VERSION ""

NS_ :

BS_:

BU_: XXX

BO_ 85 CID_ERABSH: 8 XXX
 SG_ sig_twactk : 40|1@1+ (1,0) [0|1] "" XXX
 SG_ sig_pllnsu : 56|8@1+ (1,0) [0|255] "" XXX

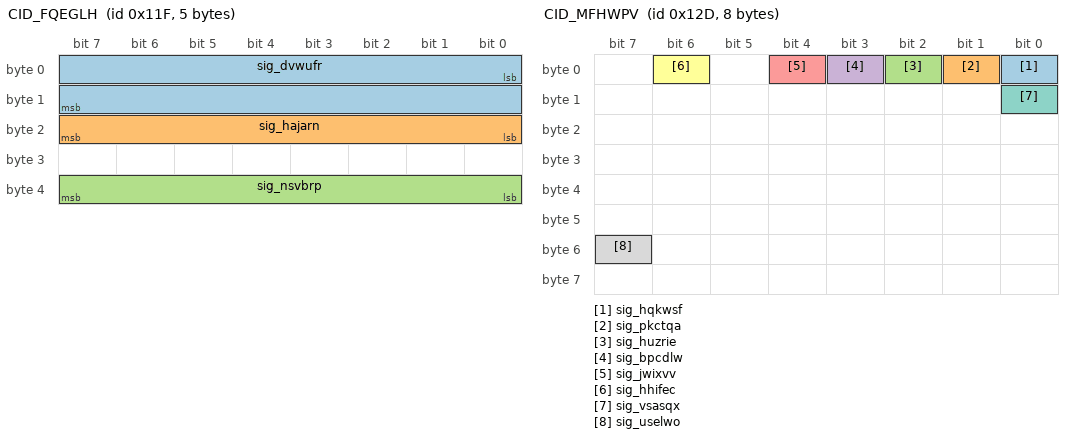
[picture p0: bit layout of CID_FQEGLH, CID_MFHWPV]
BO_ 287 CID_FQEGLH: 5 XXX
 SG_ sig_dvwufr : 0|16@1- (0.1,0) [-450|450] "" XXX
 SG_ sig_hajarn : 16|8@1+ (4,0) [0|1020] "" XXX
 SG_ sig_nsvbrp : 32|8@1+ (1,0) [0|255] "" XXX

BO_ 289 CID_NCPCTA: 8 XXX
 SG_ sig_chrfgo : 0|12@1+ (1,0) [0|255] "" XXX

BO_ 301 CID_MFHWPV: 8 XXX
 SG_ sig_hqkwsf : 0|1@0+ (1,0) [0|1] "" XXX
 SG_ sig_pkctqa : 1|1@0+ (1,0) [0|1] "" XXX
 SG_ sig_huzrie : 2|1@0+ (1,0) [0|1] "" XXX
 SG_ sig_bpcdlw : 3|1@0+ (1,0) [0|1] "" XXX
 SG_ sig_jwixvv : 4|1@0+ (1,0) [0|1] "" XXX
 SG_ sig_hhifec : 6|1@0+ (1,0) [0|1] "" XXX
 SG_ sig_vsasqx : 8|1@0+ (1,0) [0|1] "" XXX
 SG_ sig_uselwo : 55|1@0+ (1,0) [0|1] "" XXX

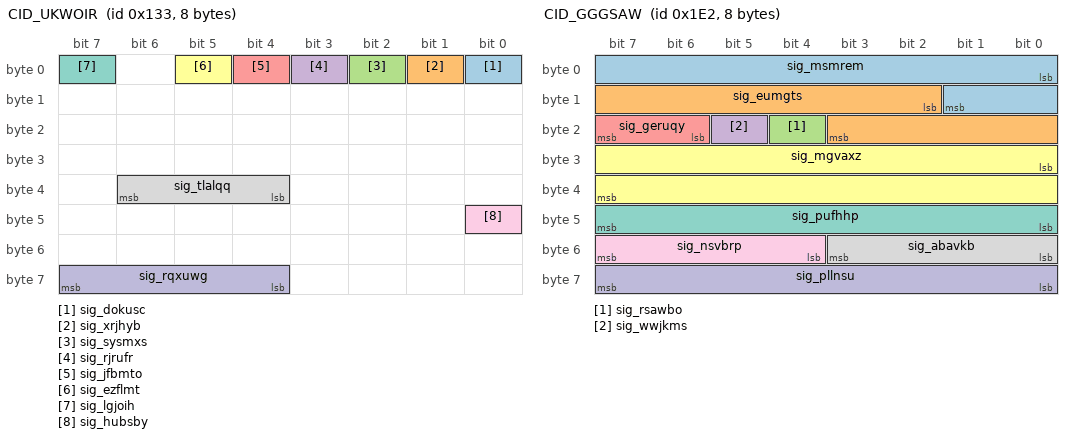
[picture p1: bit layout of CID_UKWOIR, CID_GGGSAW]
BO_ 307 CID_UKWOIR: 8 XXX
 SG_ sig_dokusc : 0|1@0+ (1,0) [0|1] "" XXX
 SG_ sig_xrjhyb : 1|1@1+ (1,0) [0|1] "" XXX
 SG_ sig_sysmxs : 2|1@1+ (1,0) [0|1] "" XXX
 SG_ sig_rjrufr : 3|1@1+ (1,0) [0|1] "" XXX
 SG_ sig_jfbmto : 4|1@0+ (1,0) [0|1] "" XXX
 SG_ sig_ezflmt : 5|1@0+ (1,0) [0|1] "" XXX
 SG_ sig_lgjoih : 7|1@0+ (1,0) [0|1] "" XXX
 SG_ sig_tlalqq : 36|3@1+ (1,0) [0|7] "" XXX
 SG_ sig_hubsby : 40|1@0+ (1,0) [0|1] "" XXX
 SG_ sig_rqxuwg : 63|4@0+ (1,0) [0|15] "" XXX

BO_ 482 CID_GGGSAW: 8 XXX
 SG_ sig_msmrem : 0|10@1- (0.01,0) [0|5] "" XXX
 SG_ sig_eumgts : 10|10@1- (0.01,0) [-5|0] "" XXX
 SG_ sig_rsawbo : 20|1@0+ (1,0) [0|1] "" XXX
 SG_ sig_wwjkms : 21|1@0+ (1,0) [0|1] "" XXX
 SG_ sig_geruqy : 22|2@1+ (1,0) [0|1] "" XXX
 SG_ sig_mgvaxz : 24|16@1- (0.1,0) [-780|779.9] "" XXX
 SG_ sig_pufhhp : 47|8@0+ (1,0) [0|255] "" XXX
 SG_ sig_abavkb : 48|4@1+ (1,0) [0|15] "" XXX
 SG_ sig_nsvbrp : 52|4@1+ (1,0) [0|15] "" XXX
 SG_ sig_pllnsu : 56|8@1+ (1,0) [0|255] "" XXX

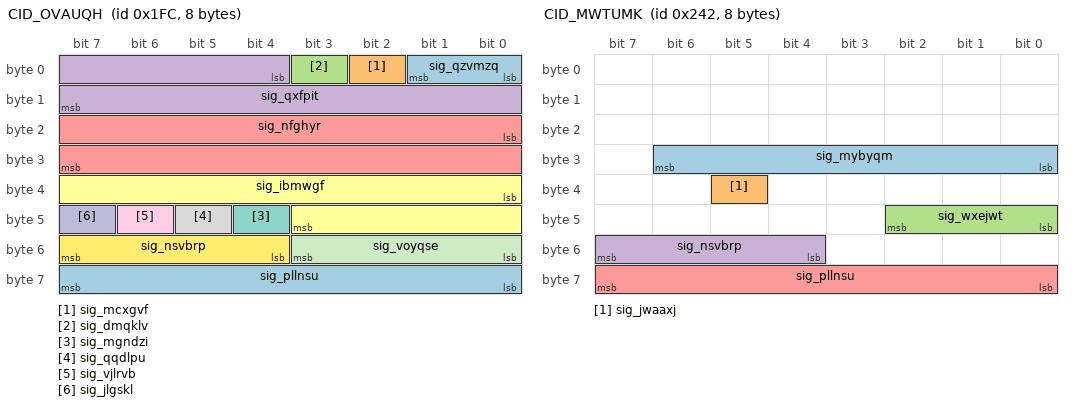
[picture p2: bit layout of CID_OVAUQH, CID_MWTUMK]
BO_ 508 CID_OVAUQH: 8 XXX
 SG_ sig_qzvmzq : 0|2@1+ (1,0) [0|1] "" XXX
 SG_ sig_mcxgvf : 2|1@1+ (1,0) [0|1] "" XXX
 SG_ sig_dmqklv : 3|1@0+ (1,0) [0|1] "" XXX
 SG_ sig_qxfpit : 4|12@1- (1,0) [-2048|2047] "" XXX
 SG_ sig_nfghyr : 16|16@1- (0.1,0) [-780|779.9] "Deg" XXX
 SG_ sig_ibmwgf : 32|12@1- (0.01,0) [0|63] "" XXX
 SG_ sig_mgndzi : 44|1@0+ (1,0) [0|1] "" XXX
 SG_ sig_qqdlpu : 45|1@1+ (1,0) [0|255] "" XXX
 SG_ sig_vjlrvb : 46|1@1+ (1,0) [0|1] "" XXX
 SG_ sig_jlgskl : 47|1@0+ (1,0) [0|3] "" XXX
 SG_ sig_voyqse : 48|4@1+ (1,0) [0|15] "" XXX
 SG_ sig_nsvbrp : 52|4@1+ (1,0) [0|15] "" XXX
 SG_ sig_pllnsu : 56|8@1+ (1,0) [0|255] "" XXX

BO_ 578 CID_MWTUMK: 8 XXX
 SG_ sig_mybyqm : 30|7@0+ (1,0) [0|127] "" XXX
 SG_ sig_jwaaxj : 37|1@0+ (1,0) [0|1] "" XXX
 SG_ sig_wxejwt : 40|3@1+ (1,0) [0|7] "" XXX
 SG_ sig_nsvbrp : 55|4@0+ (1,0) [0|15] "" XXX
 SG_ sig_pllnsu : 56|8@1+ (1,0) [0|255] "" XXX

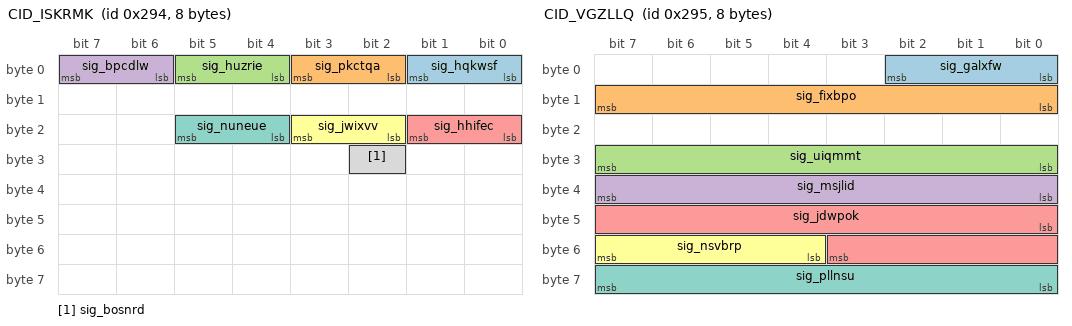
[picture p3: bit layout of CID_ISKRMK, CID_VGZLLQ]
BO_ 660 CID_ISKRMK: 8 XXX
 SG_ sig_hqkwsf : 1|2@0+ (1,0) [0|3] "" XXX
 SG_ sig_pkctqa : 3|2@0+ (1,0) [0|3] "" XXX
 SG_ sig_huzrie : 5|2@0+ (1,0) [0|3] "" XXX
 SG_ sig_bpcdlw : 7|2@0+ (1,0) [0|3] "" XXX
 SG_ sig_hhifec : 17|2@0+ (1,0) [0|3] "" XXX
 SG_ sig_jwixvv : 19|2@0+ (1,0) [0|3] "" XXX
 SG_ sig_nuneue : 21|2@0+ (1,0) [0|3] "" XXX
 SG_ sig_bosnrd : 26|1@0+ (1,0) [0|1] "" XXX

BO_ 661 CID_VGZLLQ: 8 XXX
 SG_ sig_galxfw : 2|3@0+ (1,0) [0|7] "" XXX
 SG_ sig_fixbpo : 15|8@0+ (1,0) [0|255] "" XXX
 SG_ sig_uiqmmt : 31|8@0+ (1,0) [0|255] "" XXX
 SG_ sig_msjlid : 32|8@1+ (1,0) [0|255] "" XXX
 SG_ sig_jdwpok : 40|12@1+ (1,0) [0|255] "" XXX
 SG_ sig_nsvbrp : 52|4@1+ (1,0) [0|15] "" XXX
 SG_ sig_pllnsu : 63|8@0+ (1,0) [0|255] "" XXX

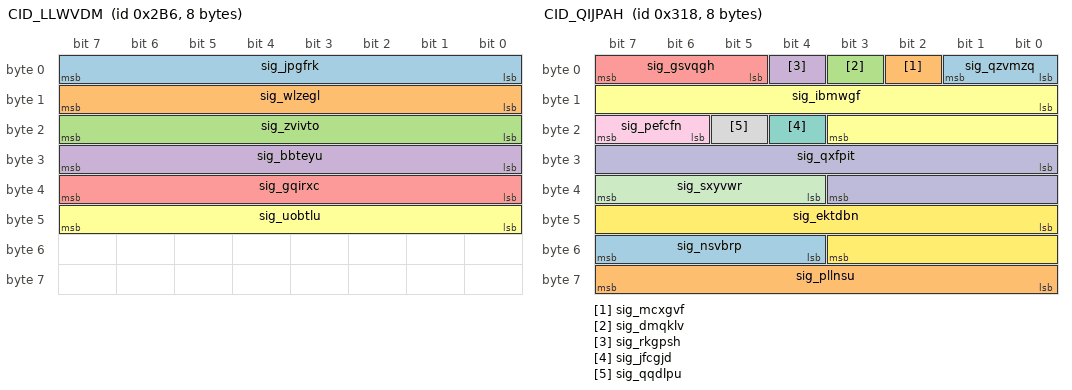
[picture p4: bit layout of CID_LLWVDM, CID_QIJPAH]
BO_ 694 CID_LLWVDM: 8 XXX
 SG_ sig_jpgfrk : 7|8@0+ (1,0) [0|255] "" XXX
 SG_ sig_wlzegl : 15|8@0+ (1,0) [0|255] "" XXX
 SG_ sig_zvivto : 23|8@0+ (1,0) [0|255] "" XXX
 SG_ sig_bbteyu : 31|8@0+ (1,0) [0|255] "" XXX
 SG_ sig_gqirxc : 39|8@0+ (1,0) [0|255] "" XXX
 SG_ sig_uobtlu : 47|8@0+ (1,0) [0|255] "" XXX

BO_ 790 CID_IHYLFP: 8 XXX
 SG_ sig_yiwmwi : 3|4@0+ (1,0) [0|1] "" XXX
 SG_ sig_asaiym : 4|2@1+ (1,0) [0|3] "" XXX
 SG_ sig_ujzcro : 6|2@1+ (1,0) [0|3] "" XXX
 SG_ sig_ppxvnu : 8|2@1+ (1,0) [0|3] "" XXX
 SG_ sig_ufomys : 10|1@1+ (1,0) [0|1] "" XXX
 SG_ sig_vddbsz : 11|4@1+ (1,0) [0|1] "" XXX
 SG_ sig_ttslhu : 15|1@0+ (1,0) [0|1] "" XXX
 SG_ sig_mgvaxz : 16|11@1- (1,0) [-1024|1023] "" XXX
 SG_ sig_rsawbo : 27|1@1+ (1,0) [0|1] "" XXX
 SG_ sig_wwjkms : 28|1@1+ (1,0) [0|3] "" XXX
 SG_ sig_pwhlfk : 29|1@0+ (1,0) [0|1] "" XXX
 SG_ sig_rqfpio : 30|1@0+ (1,0) [0|1] "" XXX
 SG_ sig_guihfw : 31|1@0+ (1,0) [0|1] "" XXX
 SG_ sig_iqlfnf : 32|2@1+ (1,0) [0|3] "" XXX
 SG_ sig_sonppl : 34|2@1+ (1,0) [0|3] "" XXX
 SG_ sig_ppvyhq : 36|4@1+ (1,0) [0|3] "" XXX
 SG_ sig_fupsdz : 40|8@1+ (5,-5) [-5|1270] "" XXX
 SG_ sig_xygpyq : 49|2@0+ (1,0) [0|3] "" XXX
 SG_ sig_pidyni : 51|2@0+ (1,0) [0|3] "" XXX
 SG_ sig_nsvbrp : 52|4@1+ (1,0) [0|15] "" XXX
 SG_ sig_pllnsu : 56|8@1+ (1,0) [0|15] "" XXX

BO_ 792 CID_QIJPAH: 8 XXX
 SG_ sig_qzvmzq : 0|2@1+ (1,0) [0|1] "" XXX
 SG_ sig_mcxgvf : 2|1@1+ (1,0) [0|1] "" XXX
 SG_ sig_dmqklv : 3|1@1+ (1,0) [0|1] "" XXX
 SG_ sig_rkgpsh : 4|1@1+ (1,0) [0|1] "" XXX
 SG_ sig_gsvqgh : 5|3@1+ (1,0) [0|1] "" XXX
 SG_ sig_ibmwgf : 8|12@1- (1,0) [-2048|2047] "" XXX
 SG_ sig_jfcgjd : 20|1@1+ (1,0) [0|1] "" XXX
 SG_ sig_qqdlpu : 21|1@1+ (1,0) [0|1] "" XXX
 SG_ sig_pefcfn : 22|2@1+ (1,0) [0|15] "" XXX
 SG_ sig_qxfpit : 24|12@1- (1,0) [-2048|2047] "" XXX
 SG_ sig_sxyvwr : 36|4@1+ (1,0) [0|15] "" XXX
 SG_ sig_ektdbn : 40|12@1+ (1,0) [0|4095] "" XXX
 SG_ sig_nsvbrp : 52|4@1+ (1,0) [0|15] "" XXX
 SG_ sig_pllnsu : 56|8@1+ (1,0) [0|255] "" XXX

BO_ 813 CID_ZQVDSF: 8 XXX
 SG_ sig_lllhgp : 0|9@1+ (0.5,0) [0|255.5] "" XXX
 SG_ sig_jggloe : 9|1@1+ (1,0) [0|1] "" XXX
 SG_ sig_tagrcv : 10|3@1+ (1,0) [0|7] "" XXX
 SG_ sig_yhjoqu : 13|3@1+ (1,0) [0|7] "" XXX
 SG_ sig_gesmbk : 16|1@1+ (1,0) [0|1] "" XXX
 SG_ sig_vnttzo : 17|1@1+ (1,0) [0|1] "" XXX
 SG_ sig_dmqklv : 18|1@1+ (1,0) [0|1] "" XXX
 SG_ sig_zqnlqf : 19|3@1+ (1,0) [0|1] "" XXX
 SG_ sig_korvsq : 22|1@0+ (1,0) [0|1] "" XXX
 SG_ sig_lfufbj : 23|1@0+ (1,0) [0|1] "" XXX
 SG_ sig_ppxvnu : 24|1@1+ (1,0) [0|1] "" XXX
 SG_ sig_vjhzxb : 25|7@1+ (1,0) [0|127] "" XXX
 SG_ sig_ljyeyu : 32|4@1+ (1,0) [0|15] "" XXX
 SG_ sig_upchqc : 36|12@1+ (1,0) [0|4095] "" XXX
 SG_ sig_nsvbrp : 48|4@1+ (1,0) [0|15] "" XXX
 SG_ sig_appgiu : 55|4@0+ (1,0) [0|15] "" XXX
 SG_ sig_pllnsu : 56|8@1+ (1,0) [0|255] "" XXX

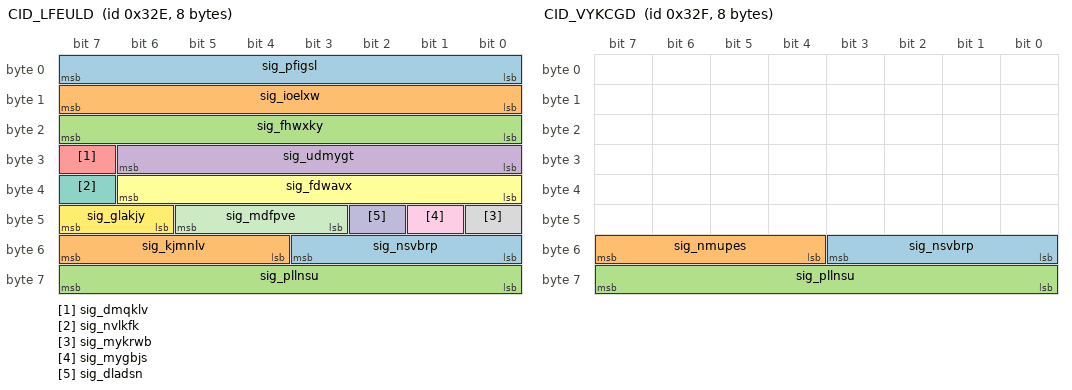
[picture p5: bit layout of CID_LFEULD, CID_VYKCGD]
BO_ 814 CID_LFEULD: 8 XXX
 SG_ sig_pfigsl : 0|8@1+ (0.05,-5) [-100|155] "" XXX
 SG_ sig_ioelxw : 8|8@1+ (0.05,-5) [0|1.26] "" XXX
 SG_ sig_fhwxky : 16|8@1+ (0.05,-5) [0|1.26] "" XXX
 SG_ sig_udmygt : 24|7@1+ (0.2,0) [0|12.7] "" XXX
 SG_ sig_dmqklv : 31|1@0+ (1,0) [0|1] "" XXX
 SG_ sig_fdwavx : 32|7@1+ (0.2,-16) [0|12.7] "" XXX
 SG_ sig_nvlkfk : 39|1@0+ (1,0) [0|1] "" XXX
 SG_ sig_mykrwb : 40|1@0+ (1,0) [0|1] "" XXX
 SG_ sig_mygbjs : 41|1@0+ (1,0) [0|1] "" XXX
 SG_ sig_dladsn : 42|1@1+ (1,0) [0|3] "" XXX
 SG_ sig_mdfpve : 45|3@0+ (1,0) [0|1] "" XXX
 SG_ sig_glakjy : 46|2@1+ (1,0) [0|3] "" XXX
 SG_ sig_nsvbrp : 48|4@1+ (1,0) [0|15] "" XXX
 SG_ sig_kjmnlv : 55|4@0+ (1,0) [0|15] "" XXX
 SG_ sig_pllnsu : 56|8@1+ (1,0) [0|255] "" XXX

BO_ 815 CID_VYKCGD: 8 XXX
 SG_ sig_nsvbrp : 48|4@1+ (1,0) [0|15] "" XXX
 SG_ sig_nmupes : 55|4@0+ (1,0) [0|15] "" XXX
 SG_ sig_pllnsu : 56|8@1+ (1,0) [0|255] "" XXX

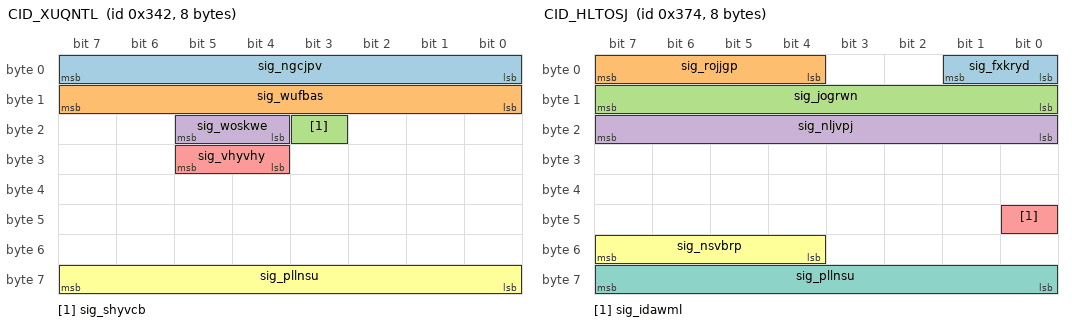
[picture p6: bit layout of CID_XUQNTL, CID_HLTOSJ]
BO_ 834 CID_XUQNTL: 8 XXX
 SG_ sig_ngcjpv : 0|8@1+ (0.01,0) [0|2.55] "" XXX
 SG_ sig_wufbas : 8|8@1+ (0.01,0) [0|2.55] "" XXX
 SG_ sig_shyvcb : 19|1@1+ (1,0) [0|1] "" XXX
 SG_ sig_woskwe : 20|2@1+ (1,0) [0|255] "" XXX
 SG_ sig_vhyvhy : 28|2@1+ (1,0) [0|1] "" XXX
 SG_ sig_pllnsu : 56|8@1+ (1,0) [0|255] "" XXX

BO_ 884 CID_HLTOSJ: 8 XXX
 SG_ sig_fxkryd : 1|2@0+ (1,0) [0|3] "" XXX
 SG_ sig_rojjgp : 7|4@0+ (1,0) [0|15] "" XXX
 SG_ sig_jogrwn : 15|8@0+ (0.1,-12) [0|255] "" XXX
 SG_ sig_nljvpj : 23|8@0+ (1,-100) [0|255] "" XXX
 SG_ sig_idawml : 40|1@0+ (1,0) [0|3] "" XXX
 SG_ sig_nsvbrp : 52|4@1+ (1,0) [0|15] "" XXX
 SG_ sig_pllnsu : 56|8@1+ (1,0) [0|255] "" XXX

BO_ 944 CID_HXWUYZ: 8 XXX
 SG_ sig_optigr : 1|2@0+ (1,0) [0|3] "" XXX
 SG_ sig_ljqrtd : 2|1@0+ (1,0) [0|1] "" XXX
 SG_ sig_urkcxn : 4|2@0+ (1,0) [0|3] "" XXX
 SG_ sig_yyklty : 5|1@0+ (1,0) [0|1] "" XXX
 SG_ sig_dauvqh : 6|1@0+ (1,0) [0|1] "" XXX
 SG_ sig_hklgix : 7|1@0+ (1,0) [0|1] "" XXX
 SG_ sig_fxhrlt : 8|1@0+ (1,0) [0|1] "" XXX
 SG_ sig_dsxdaz : 11|3@0+ (1,0) [0|7] "" XXX
 SG_ sig_kgquts : 12|1@0+ (1,0) [0|1] "" XXX
 SG_ sig_fgorot : 14|2@0+ (1,0) [0|3] "" XXX
 SG_ sig_gzwdpi : 15|1@0+ (1,0) [0|1] "" XXX
 SG_ sig_ygfaoj : 16|1@0+ (1,0) [0|1] "" XXX
 SG_ sig_butnkb : 18|2@0+ (1,0) [0|3] "" XXX
 SG_ sig_xyvooe : 19|1@0+ (1,0) [0|1] "" XXX
 SG_ sig_icifsz : 23|4@0+ (1,0) [0|15] "" XXX
 SG_ sig_svozqt : 24|28@1+ (1,0) [0|268435455] "" XXX
 SG_ sig_nsvbrp : 52|4@1+ (1,0) [0|15] "" XXX
 SG_ sig_pllnsu : 56|8@1+ (1,0) [0|255] "" XXX

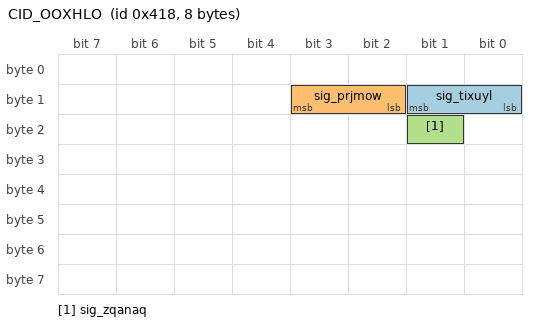
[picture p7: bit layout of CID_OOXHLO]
BO_ 1048 CID_OOXHLO: 8 XXX
 SG_ sig_tixuyl : 9|2@0+ (1,0) [0|1] "" XXX
 SG_ sig_prjmow : 11|2@0+ (1,0) [0|1] "" XXX
 SG_ sig_zqanaq : 17|1@0+ (1,0) [0|1] "" XXX

VAL_ 578 sig_wxejwt 4 "D" 2 "R" 3 "N" 1 "P";
VAL_ 790 sig_yiwmwi 11 "AutoFullBeamActive" 2 "AutoFullBeamInactive";
VAL_ 790 sig_asaiym 0 "GRAY" 1 "GREEN" 2 "YELLOW" 3 "RED";
VAL_ 790 sig_ujzcro 3 "ALARM_AND_LKA" 2 "LKA" 1 "ALARM" 0 "DISABLE";
VAL_ 790 sig_sonppl 0 "GRAY" 1 "GREEN" 2 "YELLOW" 3 "RED";
VAL_ 790 sig_xygpyq 0 "VIBRATION" 1 "AUDIO" 2 "AUDIO_AND_VIBRATION";
VAL_ 792 sig_qzvmzq 0 "NotReady" 1 "Ready" 2 "Active" 3 "TemporaryFail";
VAL_ 813 sig_tagrcv 4 "4BAR" 3 "3BAR" 2 "2BAR" 1 "1BAR";
VAL_ 813 sig_zqnlqf 0 "OFF" 2 "ACC_ON" 3 "ACC_ACTIVE" 5 "FORCE_ACCEL" 7 "ERROR";
VAL_ 813 sig_vjhzxb 36 "ACC_ERROR" 22 "OVERRIDE" 12 "ENGAGE" 8 "DISENGAGE" 20 "ACC_ON" 32 "ACC_OFF" 48 "CHECK_GEAR_D" 16 "FORCE_ACCEL" 0 "NONE";
VAL_ 814 sig_mdfpve 0 "Off" 1 "Passive" 2 "StandBy" 3 "ActiveControl" 4 "BrakeOnly" 5 "Override" 6 "Standstill" 7 "Failure";
VAL_ 814 sig_glakjy 0 "Softoff" 1 "Fastoff" 2 "Immediateoff" 3 "Initial";
VAL_ 834 sig_woskwe 2 "SPORT" 1 "ECO" 0 "SNOW";
VAL_ 834 sig_vhyvhy 3 "HEV" 2 "FORCE_EV" 1 "EV";
VAL_ 944 sig_urkcxn 0 "NOTPRESSED" 1 "DOWN_SETSPEED" 3 "UP_RESETSPEED";
